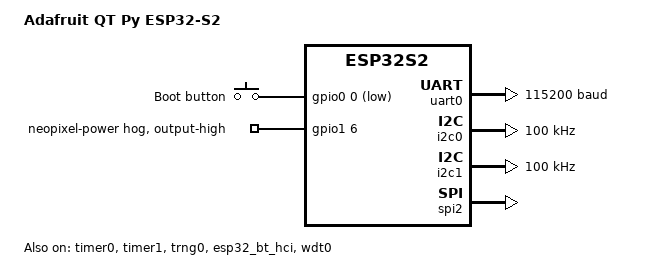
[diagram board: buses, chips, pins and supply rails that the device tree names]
/*
 * Copyright (c) 2025 Lucian Copeland for Adafruit Industries
 *
 * SPDX-License-Identifier: Apache-2.0
 */

/dts-v1/;

#include <espressif/esp32s2/esp32s2.dtsi>
#include <zephyr/dt-bindings/input/input-event-codes.h>
#include "qt_py_esp32s2-pinctrl.dtsi"
#include "seeed_xiao_connector.dtsi"
#include <espressif/partitions_0x1000_default.dtsi>

/ {
	model = "Adafruit QT Py ESP32-S2";
	compatible = "adafruit,adafruit_qt_py_esp32s2","espressif,esp32s2";

	aliases {
		sw0 = &boot_button;
		i2c-0 = &i2c0;
		watchdog0 = &wdt0;
	};

	chosen {
		zephyr,sram = &sram1;
		zephyr,console = &uart0;
		zephyr,shell-uart = &uart0;
		zephyr,flash = &flash0;
		zephyr,code-partition = &slot0_partition;
		zephyr,bt-hci = &esp32_bt_hci;
	};

	gpio_keys {
		compatible = "gpio-keys";
		boot_button: boot_button {
			label = "Boot button";
			gpios = <&gpio0 0 (GPIO_PULL_UP | GPIO_ACTIVE_LOW)>;
			zephyr,code = <INPUT_KEY_0>;
		};
	};
};

&flash0 {
	reg = <0x0 DT_SIZE_M(4)>;
};

&uart0 {
	status = "okay";
	current-speed = <115200>;
	pinctrl-0 = <&uart0_default>;
	pinctrl-names = "default";
};

&i2c0 {
	status = "okay";
	clock-frequency = <I2C_BITRATE_STANDARD>;
	pinctrl-0 = <&i2c0_default>;
	pinctrl-names = "default";
};

&i2c1 {
	status = "okay";
	clock-frequency = <I2C_BITRATE_STANDARD>;
	pinctrl-0 = <&i2c1_default>;
	pinctrl-names = "default";
};

&spi2 {
	#address-cells = <1>;
	#size-cells = <0>;
	status = "okay";
	pinctrl-0 = <&spim2_default>;
	pinctrl-names = "default";
};

&gpio0 {
	status = "okay";
};

&gpio1 {
	status = "okay";

	neopixel-power {
		gpio-hog;
		gpios = <6 GPIO_ACTIVE_HIGH>;
		output-high;
	};
};

&timer0 {
	status = "okay";
};

&timer1 {
	status = "okay";
};

&trng0 {
	status = "okay";
};

&esp32_bt_hci {
	status = "okay";
};

&wdt0 {
	status = "okay";
};
